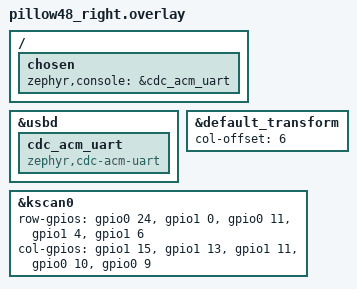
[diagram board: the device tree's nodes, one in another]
#include <dt-bindings/zmk/matrix_transform.h>
#include "pillow48.dtsi"

&usbd {
    status = "okay";
    cdc_acm_uart: cdc_acm_uart {
        compatible = "zephyr,cdc-acm-uart";
    };
};
/ {
    chosen {
        zephyr,console = &cdc_acm_uart;
    };
};

&default_transform {
    col-offset = <6>;  
};

&kscan0 {
    row-gpios = <&gpio0 24 (GPIO_ACTIVE_HIGH | GPIO_PULL_DOWN)>, 
                <&gpio1 0 (GPIO_ACTIVE_HIGH | GPIO_PULL_DOWN)>,
                <&gpio0 11 (GPIO_ACTIVE_HIGH | GPIO_PULL_DOWN)>,
                <&gpio1 4 (GPIO_ACTIVE_HIGH | GPIO_PULL_DOWN)>,
                <&gpio1 6 (GPIO_ACTIVE_HIGH | GPIO_PULL_DOWN)>;

    col-gpios = <&gpio1 15 GPIO_ACTIVE_HIGH>,
                <&gpio1 13 GPIO_ACTIVE_HIGH>,
                <&gpio1 11 GPIO_ACTIVE_HIGH>,
                <&gpio0 10 GPIO_ACTIVE_HIGH>,
                <&gpio0 9 GPIO_ACTIVE_HIGH>;
};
